AUTOSAR XML (schema 00050)
package /MICROSAR/EcuM_swc
  mode declaration group EcuM_Mode: initial-mode=STARTUP
    6 x mode:
      STARTUP
      RUN
      POST_RUN
      SLEEP
      WAKE_SLEEP
      SHUTDOWN
  data type mapping set EcuMMode_DataTypeMappingSet: mode-request-type-map{implementation-data-type=EcuM_StateType, mode-group=EcuM_Mode}  # Data Mapping for the Mode Declaration Group EcuMMode.
package /MICROSAR/EcuM_swc/DataTypes
  6 x impl type, all with category=TYPE_REFERENCE:
    EcuM_StateType: compu {80=ECUM_STATE_SLEEP, 128=ECUM_STATE_OFF, 144=ECUM_STATE_RESET}, range raw 0..144, implementation-data-type=uint8
    EcuM_ModeType: compu {2=EcuMConf_EcuMResetMode_ECUM_RESET_IO, 0=EcuMConf_EcuMResetMode_ECUM_RESET_MCU, 3=EcuMConf_EcuMResetMode_ECUM_RESET_WAKEUP, 1=EcuMConf_EcuMResetMode_ECUM_RESET_WDG}, range raw 0..3, implementation-data-type=uint8  # ECU State Manager states.
    EcuM_TimeType: range raw 0..4294967295, implementation-data-type=uint32
    EcuM_ShutdownCauseType: compu {0=EcuMConf_EcuMShutdownCause_ECUM_CAUSE_UNKNOWN, 3=EcuMConf_EcuMShutdownCause_ECUM_CAUSE_DCM, 1=EcuMConf_EcuMShutdownCause_ECUM_CAUSE_ECU_STATE, 2=EcuMConf_EcuMShutdownCause_ECUM_CAUSE_WDGM}, range raw 0..3, implementation-data-type=uint8  # This type describes the cause for a shutdown by the ECU State Manager. It can be extended by configuration.
    EcuM_BootTargetType: compu {0=ECUM_BOOT_TARGET_APP, 1=ECUM_BOOT_TARGET_OEM_BOOTLOADER, 2=ECUM_BOOT_TARGET_SYS_BOOTLOADER}, range raw 0..2, implementation-data-type=uint8  # This type represents the boot targets the ECU Manager module can be configured with. The default boot target is ECUM_BOOT_TARGET_OEM_BOOTLOADER.
    EcuM_UserType: compu {0=EcuMConf_EcuMFixedUserConfig_EcuMFixedUserConfig}, range raw 0..255, implementation-data-type=uint8  # Unique value for each user
package /MICROSAR/EcuM_swc/Interfaces
  client server interface EcuM_ShutdownTarget: is-service=true, service-kind=ECU-MANAGER  # A SW-C can select a shutdown target using this interface.
    5 x operation, all with possible-error=EcuM_ShutdownTarget/E_NOT_OK:
      SelectShutdownTarget  # The SW-C selects the cause corresponding to the next shutdown target.
        arg targetState: type=EcuM_StateType, direction=IN  # The selected shutdown cause.
        arg resetSleepMode: type=EcuM_ModeType, direction=IN  # The sleep mode (if target is ECUM_STATE_SLEEP) or the reset mechanism (if target is ECUM_STATE_RESET) of the shutdown.
      GetShutdownTarget  # Returns the currently selected shutdown target for the next shutdown as set by the operation SelectShutdownTarget.
        arg target: type=EcuM_StateType, direction=OUT  # The shutdown target of the next shutdown.
        arg resetSleepMode: type=EcuM_ModeType, direction=OUT  # The sleep mode (if target is ECUM_STATE_SLEEP) or the reset mechanism (if target is ECUM_STATE_RESET) of the shutdown.
      GetLastShutdownTarget  # Returns the shutdown target of the previous shutdown.
        arg target: type=EcuM_StateType, direction=OUT  # The shutdown target of the previous shutdown.
        arg resetSleepMode: type=EcuM_ModeType, direction=OUT  # The sleep mode (if target is ECUM_STATE_SLEEP) or the reset mechanism (if target is ECUM_STATE_RESET) of the shutdown.
      SelectShutdownCause  # The SW-C selects the cause corresponding to the next shutdown target.
        arg shutdownCause: type=EcuM_ShutdownCauseType, direction=IN  # The selected shutdown cause.
      GetShutdownCause  # Returns the selected shutdown cause as set by the operation SelectShutdownCause.
        arg shutdownCause: type=EcuM_ShutdownCauseType, direction=OUT  # The selected cause of the next shutdown.
    error E_NOT_OK: error-code=1  # The new shutdown target was not set
  client server interface EcuM_BootTarget: is-service=true, service-kind=ECU-MANAGER
    operation SelectBootTarget: possible-error=EcuM_BootTarget/E_NOT_OK  # The SW-C selects a boot target.
      arg BootTarget: type=EcuM_BootTargetType, direction=IN  # The selected boot target.
    operation GetBootTarget: possible-error=EcuM_BootTarget/E_NOT_OK  # Returns the current boot target.
      arg BootTarget: type=EcuM_BootTargetType, direction=OUT  # The currently selected boot target.
    error E_NOT_OK: error-code=1  # The new boot target was not accepted by EcuM
  mode switch interface EcuM_CurrentMode: is-service=true, service-kind=ECU-MANAGER  # Interface to read the current ECU mode
    mode group currentMode: type=EcuM_Mode
  client server interface EcuM_StateRequest: is-service=true, service-kind=ECU-MANAGER  # A SW-C which wants to keep the ECU alive shall require the client-server interface EcuM_StateRequest.
    5 x operation, all with possible-error=EcuM_StateRequest/E_NOT_OK:
      ReleasePOSTRUN  # Release of the POST_RUN state.
      ReleaseRUN  # Release of the RUN state.
      RequestPOSTRUN  # Request for the POST_RUN state.
      RequestRUN  # Request for the RUN state.
      GetStateWrapper  # Returns the current module state of the ECUM.
        arg state: type=EcuM_StateType, direction=OUT  # Reference to the actually EcuM state.
    error E_NOT_OK: error-code=1  # The request was not accepted by EcuM, a detailed error condition was sent to DET
package /MICROSAR/EcuM_swc/ComponentTypes
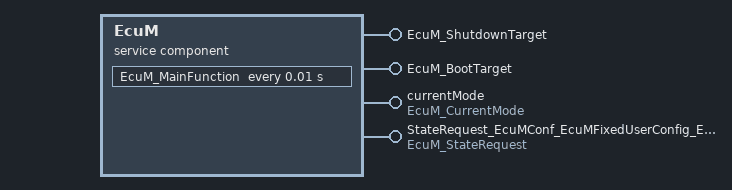
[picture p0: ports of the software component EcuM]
  service sw component type EcuM: category=SERVICE_COMPONENT
    4 x provide port:
      EcuM_ShutdownTarget: provided-interface=EcuM_ShutdownTarget
      EcuM_BootTarget: provided-interface=EcuM_BootTarget
      currentMode: mode-switch-sender-com-spec{mode-group=currentMode, mode-switched-ack=timeout=0}, provided-interface=EcuM_CurrentMode
      StateRequest_EcuMConf_EcuMFixedUserConfig_EcuMFixedUserConfig: provided-interface=EcuM_StateRequest
    behavior EcuMInternalBehavior: data-type-mapping=EcuMMode_DataTypeMappingSet, handle-termination-and-restart=NO-SUPPORT, included-data-type-set=data-type=[EcuM_StateType, EcuM_ModeType, EcuM_TimeType, EcuM_UserType, EcuM_ShutdownCauseType, EcuM_BootTargetType]
      timing event Timer_EcuM_MainFunction: start-on-event=EcuM_MainFunction, period=0.01
      12 x operation invoked event:
        OpEventSelectShutdownTarget_SelectShutdownTarget_EcuM_ShutdownTarget: start-on-event=SelectShutdownTarget, operation=EcuM_ShutdownTarget.SelectShutdownTarget
        OpEventGetShutdownTarget_GetShutdownTarget_EcuM_ShutdownTarget: start-on-event=GetShutdownTarget, operation=EcuM_ShutdownTarget.GetShutdownTarget
        OpEventGetLastShutdownTarget_GetLastShutdownTarget_EcuM_ShutdownTarget: start-on-event=GetLastShutdownTarget, operation=EcuM_ShutdownTarget.GetLastShutdownTarget
        OpEventSelectShutdownCause_SelectShutdownCause_EcuM_ShutdownTarget: start-on-event=SelectShutdownCause, operation=EcuM_ShutdownTarget.SelectShutdownCause
        OpEventGetShutdownCause_GetShutdownCause_EcuM_ShutdownTarget: start-on-event=GetShutdownCause, operation=EcuM_ShutdownTarget.GetShutdownCause
        OpEventSelectBootTarget_SelectBootTarget_EcuM_BootTarget: start-on-event=SelectBootTarget, operation=EcuM_BootTarget.SelectBootTarget
        OpEventGetBootTarget_GetBootTarget_EcuM_BootTarget: start-on-event=GetBootTarget, operation=EcuM_BootTarget.GetBootTarget
        OpEventReleasePOSTRUN_ReleasePOSTRUN_StateRequest_EcuMConf_EcuMFixedUserConfig_EcuMFixedUserConfig: start-on-event=ReleasePOSTRUN, operation=StateRequest_EcuMConf_EcuMFixedUserConfig_EcuMFixedUserConfig.ReleasePOSTRUN
        OpEventReleaseRUN_ReleaseRUN_StateRequest_EcuMConf_EcuMFixedUserConfig_EcuMFixedUserConfig: start-on-event=ReleaseRUN, operation=StateRequest_EcuMConf_EcuMFixedUserConfig_EcuMFixedUserConfig.ReleaseRUN
        OpEventRequestPOSTRUN_RequestPOSTRUN_StateRequest_EcuMConf_EcuMFixedUserConfig_EcuMFixedUserConfig: start-on-event=RequestPOSTRUN, operation=StateRequest_EcuMConf_EcuMFixedUserConfig_EcuMFixedUserConfig.RequestPOSTRUN
        OpEventRequestRUN_RequestRUN_StateRequest_EcuMConf_EcuMFixedUserConfig_EcuMFixedUserConfig: start-on-event=RequestRUN, operation=StateRequest_EcuMConf_EcuMFixedUserConfig_EcuMFixedUserConfig.RequestRUN
        OpEventGetStateWrapper_GetStateWrapper_StateRequest_EcuMConf_EcuMFixedUserConfig_EcuMFixedUserConfig: start-on-event=GetStateWrapper, operation=StateRequest_EcuMConf_EcuMFixedUserConfig_EcuMFixedUserConfig.GetStateWrapper
      port-api-options:
        enable-take-address=true, indirect-api=false, port=currentMode
        enable-take-address=true, indirect-api=false, port=EcuM_ShutdownTarget
        enable-take-address=true, indirect-api=false, port=EcuM_BootTarget
        {enable-take-address=true, indirect-api=false, port-defined-argument-value{value=user:0, value-type=EcuM_UserType}, port=StateRequest_EcuMConf_EcuMFixedUserConfig_EcuMFixedUserConfig}
      13 x runnable:
        EcuM_MainFunction
          mode switch point ModeSwitchPointEcuM_MainFunction_currentMode_currentMode: mode-group=currentMode.currentMode
        SelectShutdownTarget: can-be-invoked-concurrently=true, symbol=EcuM_SelectShutdownTarget
        GetShutdownTarget: can-be-invoked-concurrently=true, symbol=EcuM_GetShutdownTarget
        GetLastShutdownTarget: can-be-invoked-concurrently=true, symbol=EcuM_GetLastShutdownTarget
        SelectShutdownCause: can-be-invoked-concurrently=true, symbol=EcuM_SelectShutdownCause
        GetShutdownCause: can-be-invoked-concurrently=true, symbol=EcuM_GetShutdownCause
        SelectBootTarget: can-be-invoked-concurrently=true, symbol=EcuM_SelectBootTarget
        GetBootTarget: can-be-invoked-concurrently=true, symbol=EcuM_GetBootTarget
        ReleasePOSTRUN: can-be-invoked-concurrently=true, symbol=EcuM_ReleasePOST_RUN
        ReleaseRUN: can-be-invoked-concurrently=true, symbol=EcuM_ReleaseRUN
        RequestPOSTRUN: can-be-invoked-concurrently=true, symbol=EcuM_RequestPOST_RUN
        RequestRUN: can-be-invoked-concurrently=true, symbol=EcuM_RequestRUN
        GetStateWrapper: can-be-invoked-concurrently=true, symbol=EcuM_GetStateWrapper
  swc implementation EcuMImplementation: programming-language=C, behavior=EcuMInternalBehavior
    resource consumption EcuMResourceConsumption
      5 x memory section:
        EcuM_START_SEC_CODE: sw-addrmethod=CODE, symbol=CODE
        EcuM_START_SEC_CONST_UNSPECIFIED: alignment=UNSPECIFIED, sw-addrmethod=CONST, symbol=CONST_UNSPECIFIED
        EcuM_START_SEC_VAR_NOINIT_UNSPECIFIED: alignment=UNSPECIFIED, sw-addrmethod=VAR_NO_INIT, symbol=VAR_NOINIT_UNSPECIFIED
        EcuM_START_SEC_VAR_INIT_UNSPECIFIED: alignment=UNSPECIFIED, sw-addrmethod=VAR_INIT, symbol=VAR_INIT_UNSPECIFIED
        EcuM_START_SEC_VAR_ZERO_INIT_UNSPECIFIED: alignment=UNSPECIFIED, sw-addrmethod=VAR_CLEARED, symbol=VAR_ZERO_INIT_UNSPECIFIED
